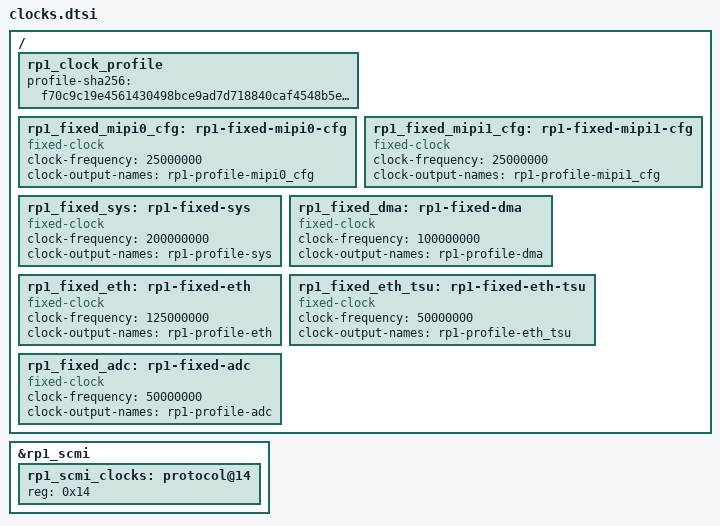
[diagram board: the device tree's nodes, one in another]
/* Generated policy definitions; transport placement is separate. */
/ {
    rp1_clock_profile {
        profile-sha256 = "f70c9c19e4561430498bce9ad7d718840caf4548b5ea9d4427218be456924e77";
    };
    rp1_fixed_mipi0_cfg: rp1-fixed-mipi0-cfg {
        compatible = "fixed-clock";
        #clock-cells = <0>;
        clock-frequency = <25000000>;
        clock-output-names = "rp1-profile-mipi0_cfg";
    };
    rp1_fixed_mipi1_cfg: rp1-fixed-mipi1-cfg {
        compatible = "fixed-clock";
        #clock-cells = <0>;
        clock-frequency = <25000000>;
        clock-output-names = "rp1-profile-mipi1_cfg";
    };
    rp1_fixed_sys: rp1-fixed-sys {
        compatible = "fixed-clock";
        #clock-cells = <0>;
        clock-frequency = <200000000>;
        clock-output-names = "rp1-profile-sys";
    };
    rp1_fixed_dma: rp1-fixed-dma {
        compatible = "fixed-clock";
        #clock-cells = <0>;
        clock-frequency = <100000000>;
        clock-output-names = "rp1-profile-dma";
    };
    rp1_fixed_eth: rp1-fixed-eth {
        compatible = "fixed-clock";
        #clock-cells = <0>;
        clock-frequency = <125000000>;
        clock-output-names = "rp1-profile-eth";
    };
    rp1_fixed_eth_tsu: rp1-fixed-eth-tsu {
        compatible = "fixed-clock";
        #clock-cells = <0>;
        clock-frequency = <50000000>;
        clock-output-names = "rp1-profile-eth_tsu";
    };
    rp1_fixed_adc: rp1-fixed-adc {
        compatible = "fixed-clock";
        #clock-cells = <0>;
        clock-frequency = <50000000>;
        clock-output-names = "rp1-profile-adc";
    };
};
&rp1_scmi {
    rp1_scmi_clocks: protocol@14 {
        reg = <0x14>;
        #clock-cells = <1>;
    };
};
